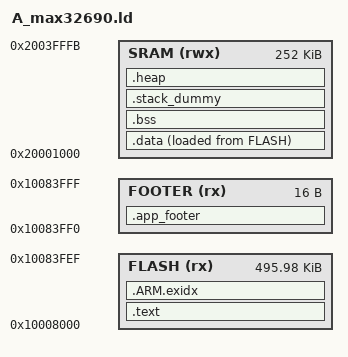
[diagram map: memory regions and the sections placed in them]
/*******************************************************************************
 * Copyright (C) 2019 Maxim Integrated Products, Inc., All Rights Reserved.
 *
 * Permission is hereby granted, free of charge, to any person obtaining a
 * copy of this software and associated documentation files (the "Software"),
 * to deal in the Software without restriction, including without limitation
 * the rights to use, copy, modify, merge, publish, distribute, sublicense,
 * and/or sell copies of the Software, and to permit persons to whom the
 * Software is furnished to do so, subject to the following conditions:
 *
 * The above copyright notice and this permission notice shall be included
 * in all copies or substantial portions of the Software.
 *
 * THE SOFTWARE IS PROVIDED "AS IS", WITHOUT WARRANTY OF ANY KIND, EXPRESS
 * OR IMPLIED, INCLUDING BUT NOT LIMITED TO THE WARRANTIES OF
 * MERCHANTABILITY, FITNESS FOR A PARTICULAR PURPOSE AND NONINFRINGEMENT.
 * IN NO EVENT SHALL MAXIM INTEGRATED BE LIABLE FOR ANY CLAIM, DAMAGES
 * OR OTHER LIABILITY, WHETHER IN AN ACTION OF CONTRACT, TORT OR OTHERWISE,
 * ARISING FROM, OUT OF OR IN CONNECTION WITH THE SOFTWARE OR THE USE OR
 * OTHER DEALINGS IN THE SOFTWARE.
 *
 * Except as contained in this notice, the name of Maxim Integrated
 * Products, Inc. shall not be used except as stated in the Maxim Integrated
 * Products, Inc. Branding Policy.
 *
 * The mere transfer of this software does not imply any licenses
 * of trade secrets, proprietary technology, copyrights, patents,
 * trademarks, maskwork rights, or any other form of intellectual
 * property whatsoever. Maxim Integrated Products, Inc. retains all
 * ownership rights.
 *
 ******************************************************************************/

MEMORY {
    /* MAX32690: Image A starts at 0x10008000 (after 16KB bootloader + 16KB commit area) */
    FLASH (rx) : ORIGIN = 0x10008000, LENGTH = 496K - 16      /* Save 16 bytes at end for CRC and image length */
    FOOTER (rx) : ORIGIN = 0x10083FF0, LENGTH = 16  /* End of 496KB image */
    /* Start SRAM after bootloader's RAM usage (0x1000 bytes) */
    SRAM (rwx) : ORIGIN = 0x20001000, LENGTH = 256K - 0x1000 - 4  /* MAX32690 has 256KB SRAM, reserve first 4KB for bootloader + 4 bytes for loader state */
}

/* Bootloader API addresses - adjusted for 16K page size */
LDR_StartDownload           = 0x10003F80;
LDR_DownloadImageBlock      = 0x10003F84;
LDR_AbortUpgrade            = 0x10003F88;
LDR_CompleteDownload        = 0x10003F8C;
LDR_RunImageA               = 0x10003F90;
LDR_RunImageB               = 0x10003F94;
LDR_CommitImageA            = 0x10003F98;
LDR_CommitImageB            = 0x10003F9C;
LDR_GetImageStatus          = 0x10003FA0;
LDR_GetVersion              = 0x10003FA4;
LDR_GetBuildDate            = 0x10003FA8;

SECTIONS {
    .text :
    {
        _text = .;
        KEEP(*(.isr_vector))
        *(.text*)    /* program code */
        *(.rodata*)  /* read-only data: "const" */

        KEEP(*(.init))
        KEEP(*(.fini))

        /* C++ Exception handling */
        KEEP(*(.eh_frame*))
        _etext = .;
    } > FLASH

    /* it's used for C++ exception handling      */
    /* we need to keep this to avoid overlapping */
    .ARM.exidx :
    {
        __exidx_start = .;
        *(.ARM.exidx*)
        __exidx_end = .;
    } > FLASH

    .data :
    {
        _data = ALIGN(., 4);
        *(.data*)           /*read-write initialized data: initialized global variable*/
        *(.spix_config*)    /* SPIX configuration functions need to be run from SRAM */

        /* These array sections are used by __libc_init_array to call static C++ constructors */
        . = ALIGN(4);
        /* preinit data */
        PROVIDE_HIDDEN (__preinit_array_start = .);
        KEEP(*(.preinit_array))
        PROVIDE_HIDDEN (__preinit_array_end = .);

        . = ALIGN(4);
        /* init data */
        PROVIDE_HIDDEN (__init_array_start = .);
        KEEP(*(SORT(.init_array.*)))
        KEEP(*(.init_array))
        PROVIDE_HIDDEN (__init_array_end = .);

        . = ALIGN(4);
        /* finit data */
        PROVIDE_HIDDEN (__fini_array_start = .);
        KEEP(*(SORT(.fini_array.*)))
        KEEP(*(.fini_array))
        PROVIDE_HIDDEN (__fini_array_end = .);

        _edata = ALIGN(., 4);
    } > SRAM AT>FLASH
    __load_data = LOADADDR(.data);

    .app_footer :
    {
        QUAD(0);
    } > FOOTER

    .bss :
    {
        . = ALIGN(4);
        _bss = .;
        *(.bss*)     /*read-write zero initialized data: uninitialzed global variable*/
        *(COMMON)
        _ebss = ALIGN(., 4);
    } > SRAM

    /* Set stack top to end of RAM, and stack limit move down by
     * size of stack_dummy section */
    __StackTop = ORIGIN(SRAM) + LENGTH(SRAM);
    __StackLimit = __StackTop - SIZEOF(.stack_dummy);

    /* .stack_dummy section doesn't contains any symbols. It is only
     * used for linker to calculate size of stack sections, and assign
     * values to stack symbols later */
    .stack_dummy (COPY):
    {
        *(.stack*)
    } > SRAM

    .heap (COPY):
    {
        . = ALIGN(4);
        *(.heap*)
        __HeapLimit = ABSOLUTE(__StackLimit);
    } > SRAM

    PROVIDE(__stack = __StackTop);

    /* Check if data + heap + stack exceeds RAM limit */
    ASSERT(__StackLimit >= _ebss, "region RAM overflowed with stack")
}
